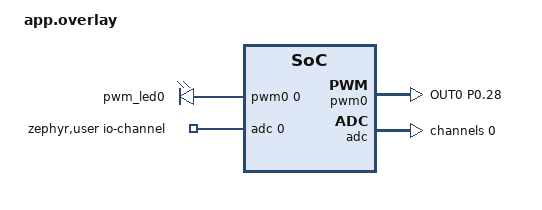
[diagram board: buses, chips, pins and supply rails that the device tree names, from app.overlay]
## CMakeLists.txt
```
cmake_minimum_required(VERSION 3.20.0)
find_package(Zephyr REQUIRED HINTS $ENV{ZEPHYR_BASE})

project(test_pwm_circuit)

target_sources(app PRIVATE src/main.c src/heater_PWM.c src/adc_temp.c src/control.c src/pid.c src/UI.c src/database.c src/display_uart.c src/filter.c)
```

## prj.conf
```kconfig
CONFIG_GPIO=y
CONFIG_PWM=y
CONFIG_LOG=y
CONFIG_PRINTK=n
CONFIG_ADC=y
CONFIG_CBPRINTF_FP_SUPPORT=y
```

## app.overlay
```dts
/ {
    aliases {
        heater = &pwm_led0;
    };

    pwmleds {
        compatible = "pwm-leds";
        pwm_led0: pwm_led_0 {
            /* Channel 0, 20ms period */
            pwms = <&pwm0 0 PWM_MSEC(20) PWM_POLARITY_NORMAL>;
        };
    };

    /* ADC User Shortcut */
    zephyr,user {
        io-channels = <&adc 0>;
    };
};

/* PWM Configuration */
&pwm0 {
    status = "okay";
    pinctrl-0 = <&pwm0_default>;
    pinctrl-1 = <&pwm0_sleep>;
    pinctrl-names = "default", "sleep";
};

&pinctrl {
    pwm0_default: pwm0_default {
        group1 {
            /* CRITICAL: Heater on Pin 28 */
            psels = <NRF_PSEL(PWM_OUT0, 0, 28)>;
        };
    };

    pwm0_sleep: pwm0_sleep {
        group1 {
            psels = <NRF_PSEL(PWM_OUT0, 0, 28)>;
            low-power-enable;
        };
    };
};

/* ADC Configuration */
&adc {
    status = "okay";
    #address-cells = <1>;
    #size-cells = <0>;

    channel@0 {
        reg = <0>;
        zephyr,gain = "ADC_GAIN_1_6";
        zephyr,reference = "ADC_REF_INTERNAL";
        zephyr,acquisition-time = <ADC_ACQ_TIME_DEFAULT>;
        zephyr,input-positive = <NRF_SAADC_AIN1>; 
        zephyr,resolution = <12>;
    };
};
```

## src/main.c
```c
#include <zephyr/kernel.h>
#include <zephyr/sys/printk.h>
#include "database.h"
#include "adc_temp.h"
#include "control.h"
#include "display_uart.h"
#include "UI.h"
#include "heater_PWM.h"
#include "filter.h"

#define DISPLAY_STACK 2048
#define STACK 1024

#define ADC_PRIORITY     1 
#define FILTER_PRIORITY  2 
#define CONTROL_PRIORITY 3 
#define PWM_PRIORITY     3 
#define LED_PRIORITY     5 
#define DISPLAY_PRIORITY 6

K_THREAD_DEFINE(adc_tid, STACK, adc_thread_entry, NULL, NULL, NULL, ADC_PRIORITY, 0, 0);
K_THREAD_DEFINE(filter_tid, STACK,  filter_thread_entry, NULL, NULL, NULL, FILTER_PRIORITY, 0, 0);
K_THREAD_DEFINE(control_tid, STACK,  control_thread, NULL, NULL, NULL, CONTROL_PRIORITY, 0, 0);
K_THREAD_DEFINE(pwm_tid, STACK,  pwm_thread_entry, NULL, NULL, NULL, PWM_PRIORITY, 0, 0);
K_THREAD_DEFINE(led_tid, STACK,  ui_led_thread_entry, NULL, NULL, NULL, LED_PRIORITY, 0, 0);
K_THREAD_DEFINE(disp_tid, DISPLAY_STACK, display_thread, NULL, NULL, NULL, DISPLAY_PRIORITY, 0, 0);

int main(void) 
{
    db_init();
    
    return 0;
}

/* RAM used: 2.66% (6976 B / 256 kB)

THREAD: ADC Acquisition
>> AVG TIME = 90 us
>> MAX TIME = 123 us

THREAD: Filter Logic
>> AVG TIME = 6 us
>> MAX TIME = 31 us

THREAD: Control Logic
>> AVG TIME = 12 us
>> MAX TIME = 31 us

THREAD: PWM Actuation
>> AVG TIME = 14 us
>> MAX TIME = 31 us

THREAD: LEDs
>> AVG TIME = 6 us
>> MAX TIME = 31 us

THREAD: Display
>> AVG TIME = 16 us
>> MAX TIME = 31 us

*/
```

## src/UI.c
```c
#include <zephyr/kernel.h>
#include <zephyr/drivers/gpio.h>
#include "database.h" 

// Hardware Aliases
#define SLEEP_TIME_MS 1000
#define DEBOUNCE_MS 200 // Average human Response Time

// Button Definition
#define BTN_ENABLE  DT_ALIAS(sw0)
#define BTN_INC     DT_ALIAS(sw1)
#define BTN_DEC     DT_ALIAS(sw3)

// LED Definition
#define LED_STATUS  DT_ALIAS(led0)
#define LED_NORM    DT_ALIAS(led1)
#define LED_LOW     DT_ALIAS(led2)
#define LED_HIGH    DT_ALIAS(led3)

static const struct gpio_dt_spec btn_enable = GPIO_DT_SPEC_GET(BTN_ENABLE, gpios);
static const struct gpio_dt_spec btn_inc    = GPIO_DT_SPEC_GET(BTN_INC, gpios);
static const struct gpio_dt_spec btn_dec    = GPIO_DT_SPEC_GET(BTN_DEC, gpios);

static const struct gpio_dt_spec led_status = GPIO_DT_SPEC_GET(LED_STATUS, gpios);
static const struct gpio_dt_spec led_norm   = GPIO_DT_SPEC_GET(LED_NORM, gpios);
static const struct gpio_dt_spec led_low    = GPIO_DT_SPEC_GET(LED_LOW, gpios);
static const struct gpio_dt_spec led_high   = GPIO_DT_SPEC_GET(LED_HIGH, gpios);

static struct gpio_callback data_enable, data_inc, data_dec;

// Debounce variables
// int64_t in all the debounce variables ensures continuous operation for millions of years
// A standard 32-bit int would overflow in approx. 24.8 days (2^31 ms)
static int64_t last_time_enable = 0;
static int64_t last_time_inc = 0;
static int64_t last_time_dec = 0;

void button_enable_handler() // Enable Button
{
    int64_t now = k_uptime_get();
    int64_t time_passed = now - last_time_enable;

    if (time_passed < DEBOUNCE_MS) {
        return; 
    } 
    else {
        last_time_enable = now;
    
        bool current_state = db_read_system_enable();
        db_write_system_enable(!current_state);
        gpio_pin_set_dt(&led_status, (int)(!current_state)); // led update
    }
}

void button_inc_handler()  // Target Increment Update
{ 
    int64_t now = k_uptime_get();
    int64_t time_passed = now - last_time_inc;

    if (time_passed < DEBOUNCE_MS) 
    {
        return;

    } else{
        last_time_inc = now;

        if (db_read_system_enable()) 
        {
        float val = db_read_target_temp();
        db_write_target_temp(val + 1.0f);
        }
    }
}

void button_dec_handler() // Target Decrement Update
{
    int64_t now = k_uptime_get();
    int64_t time_passed = now - last_time_dec;
    if (time_passed < DEBOUNCE_MS) 
    {
        return;

    } else{
        last_time_dec = now;

    if (db_read_system_enable())
    {
        float val = db_read_target_temp();
        db_write_target_temp(val - 1.0f);
    }
    }
}

int ui_init(void)   // UI Initialization
{
    
    if (!gpio_is_ready_dt(&btn_enable)) return -1;      

    gpio_pin_configure_dt(&btn_enable, GPIO_INPUT);
    gpio_pin_interrupt_configure_dt(&btn_enable, GPIO_INT_EDGE_TO_ACTIVE);     // On/Off Button Config
    gpio_pin_configure_dt(&btn_inc, GPIO_INPUT);
    gpio_pin_interrupt_configure_dt(&btn_inc, GPIO_INT_EDGE_TO_ACTIVE);        // Increment Button Config
    gpio_pin_configure_dt(&btn_dec, GPIO_INPUT);
    gpio_pin_interrupt_configure_dt(&btn_dec, GPIO_INT_EDGE_TO_ACTIVE);        // Decrement Button Config

    // LEDs Config
    gpio_pin_configure_dt(&led_status, GPIO_OUTPUT_INACTIVE);
    gpio_pin_configure_dt(&led_norm,   GPIO_OUTPUT_INACTIVE);
    gpio_pin_configure_dt(&led_low,    GPIO_OUTPUT_INACTIVE);
    gpio_pin_configure_dt(&led_high,   GPIO_OUTPUT_INACTIVE);                  

    // Associates a function whenever we click a Button
    gpio_init_callback(&data_enable, button_enable_handler, BIT(btn_enable.pin));
    gpio_add_callback(btn_enable.port, &data_enable);
    gpio_init_callback(&data_inc, button_inc_handler, BIT(btn_inc.pin)); 
    gpio_add_callback(btn_inc.port, &data_inc);
    gpio_init_callback(&data_dec, button_dec_handler, BIT(btn_dec.pin));
    gpio_add_callback(btn_dec.port, &data_dec);

    return 0;
}

void ui_led_thread_entry() 
{  
    if (ui_init() != 0)
    {
        printk("Error: UI Init Failed!\n");
    }  

    int64_t next_run_time = k_uptime_get();

    while (1)
    {
        next_run_time += 1000;

        if (!db_read_system_enable()) {
            gpio_pin_set_dt(&led_norm, 0);
            gpio_pin_set_dt(&led_low, 0);
            gpio_pin_set_dt(&led_high, 0);
        } else {
            float diff = db_read_target_temp() - db_read_current_temp();

            if (diff > 5) // Low Temperatures
            {       
                gpio_pin_set_dt(&led_low, 1);
                gpio_pin_set_dt(&led_norm, 0);
                gpio_pin_set_dt(&led_high, 0);
            } 
            else if (diff < -5) // High Temperatures
            { 
                gpio_pin_set_dt(&led_low, 0);
                gpio_pin_set_dt(&led_norm, 0);
                gpio_pin_set_dt(&led_high, 1);
            } 
            else 
            {                
                gpio_pin_set_dt(&led_low, 0);
                gpio_pin_set_dt(&led_norm, 1);
                gpio_pin_set_dt(&led_high, 0);
            }
        }
        int remaining = next_run_time - k_uptime_get();
        if (remaining > 0) k_msleep(remaining);    
    }
}

//K_THREAD_DEFINE(ui_led_tid, 1024, ui_led_thread_entry, NULL, NULL, NULL, 4, 0, 0);
```

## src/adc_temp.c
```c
#include <zephyr/kernel.h>
#include <zephyr/drivers/adc.h>
#include <zephyr/logging/log.h>
#include "adc_temp.h"
#include "database.h"

#define ADC_PERIOD_MS 1000

LOG_MODULE_REGISTER(ADC_Module, LOG_LEVEL_INF);

K_TIMER_DEFINE(adc_timer, NULL, NULL); // Drift-free, hardware-backed timing

static const struct adc_dt_spec adc_channel = ADC_DT_SPEC_GET_BY_IDX(DT_PATH(zephyr_user), 0);

static int16_t buf; 
static struct adc_sequence sequence = {
    .buffer = &buf,
    .buffer_size = sizeof(buf),

};

static float shared_raw_value = 0.0f; // Local variable to be filtered (no need to be stored in the DB)

// Local getter function
float adc_get_raw_internal(void) {
    return shared_raw_value;
}

void adc_temp_init(void) // ADC Initialization
{
    if (!adc_is_ready_dt(&adc_channel))
    {
        LOG_INF("ADC controller not ready");
    }

    int error = adc_channel_setup_dt(&adc_channel);
    if (error < 0)
    {
        LOG_INF("Could not setup channel (%d)", error);
    }

    error = adc_sequence_init_dt(&adc_channel, &sequence);
    if (error < 0) {
        LOG_INF("Error: Could not init sequence (%d)\n", error);
    }
}

void adc_thread_entry(void) {
    
    adc_temp_init();

    k_timer_start(&adc_timer, K_MSEC(ADC_PERIOD_MS), K_MSEC(ADC_PERIOD_MS));

    while (1) {
        k_timer_status_sync(&adc_timer);

        int err = adc_read(adc_channel.dev, &sequence);
        if (err == 0) {
            
            int32_t val_mv = buf; // 
            adc_raw_to_millivolts_dt(&adc_channel, &val_mv);
            float temp = (val_mv - 500) / 10.0f;

            shared_raw_value = temp;
            k_sem_give(&adc_data_sem); 
        } else {
            LOG_INF("ADC Read Error: %d\n", err);
        }
    }
}
```

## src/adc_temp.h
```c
#ifndef ADC_TEMP_H
#define ADC_TEMP_H

void adc_temp_init(void);

void adc_temp_read(void);

float adc_get_raw_internal(void);

void adc_thread_entry(void);

#endif
```

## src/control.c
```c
#include <zephyr/kernel.h>
#include <zephyr/logging/log.h>
#include "adc_temp.h"
#include "heater_PWM.h"
#include "pid.h"
#include "database.h"

LOG_MODULE_REGISTER(Control, LOG_LEVEL_INF);

// PID Parameters
#define KP  20.0f  
#define TI  130.0f 
#define TD  1.0f   

PID_Config my_pid;

K_TIMER_DEFINE(control_timer, NULL, NULL); // Drift-free, hardware-backed timing

void control_thread(void){
    
    pid_init(&my_pid, KP, TI, TD);

    k_timer_start(&control_timer, K_MSEC(1000), K_MSEC(1000));

    float dt = 1.0f; // period: 1000ms

    while (1)
    {
        k_timer_status_sync(&control_timer);
        
        // Local Reading Variables 
        float temp = db_read_current_temp();
        float target = db_read_target_temp();
        bool on = db_read_system_enable();

        int8_t power_command = 0;
        
        if (!on) {
            power_command = 0;
            pid_init(&my_pid, KP, TI, TD); 
        } else {
            power_command = (int8_t)pid_compute(&my_pid, target, temp, dt); // PID math doing its job
        }

        db_write_current_power(power_command); // current state goes straight to the database

        k_sem_give(&pwm_data_sem);
    }
    }
  
```

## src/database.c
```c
#include "database.h"

// 1. PRIVATE DATA
static volatile float  target_temp = 19.0f;
static float  current_temp = 0.0f;
//static float  raw_temp = 0.0f;  // former test
static int8_t    current_power = 0;
static volatile bool   system_enable = false;

// Semaphore Definition (they start locked)
K_SEM_DEFINE(adc_data_sem, 0, 1); 
K_SEM_DEFINE(pwm_data_sem, 0, 1);

K_MUTEX_DEFINE(db_mutex);

void db_init(void) {
    // Mutex auto-initialization
}

// ACCESS FUNCTIONS (no mutex needed in volatile variables)

/* Mutex Removed for ISR Safety
target_temp is written by an Interrupt Service Routine (ISR) via buttons.
ISRs cannot wait for mutexes. Therefore, the variable is declared 'volatile'
to prevent compiler caching which avoids race conditions without locking.
 */

void db_write_target_temp(float new_target) {
    //k_mutex_lock(&db_mutex, K_FOREVER);

    // Safety Limits
    if (new_target > 60.0f) new_target = 60.0f; 
    if (new_target < 20.0f) new_target = 20.0f;

    target_temp = new_target;
    //k_mutex_unlock(&db_mutex);
}

float db_read_target_temp(void) {
    k_mutex_lock(&db_mutex, K_FOREVER);
    float val = target_temp;
    k_mutex_unlock(&db_mutex);
    return val;
}

void db_write_current_temp(float new_temp) {
    k_mutex_lock(&db_mutex, K_FOREVER);
    current_temp = new_temp;
    k_mutex_unlock(&db_mutex);
}

float db_read_current_temp(void) {
    k_mutex_lock(&db_mutex, K_FOREVER);
    float val = current_temp;
    k_mutex_unlock(&db_mutex);
    return val;
}

void db_write_current_power(int8_t new_power) {
    k_mutex_lock(&db_mutex, K_FOREVER);
    current_power = new_power;
    k_mutex_unlock(&db_mutex);
}

int8_t db_read_current_power(void) {
    k_mutex_lock(&db_mutex, K_FOREVER);
    int8_t val = current_power;
    k_mutex_unlock(&db_mutex);
    return val;
}

void db_write_system_enable(bool enable) {
    //k_mutex_lock(&db_mutex, K_FOREVER);
    system_enable = enable;
    //k_mutex_unlock(&db_mutex);
}

bool db_read_system_enable(void) {
    k_mutex_lock(&db_mutex, K_FOREVER);
    bool val = system_enable;
    k_mutex_unlock(&db_mutex);
    return val;
}

/*  no longer used (previous test )

void db_write_raw_temp(float val) {
    k_mutex_lock(&db_mutex, K_FOREVER);
    raw_temp = val;
    k_mutex_unlock(&db_mutex);
}

float db_read_raw_temp(void) {
    k_mutex_lock(&db_mutex, K_FOREVER);
    float val = raw_temp;
    k_mutex_unlock(&db_mutex);
    return val;
}
*/
```

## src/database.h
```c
#ifndef DATABASE_H
#define DATABASE_H

#include <zephyr/kernel.h>

extern struct k_sem adc_data_sem;
extern struct k_sem pwm_data_sem;

void db_init(void); // Initialize the database (mutex)

// WRITERS
void db_write_target_temp(float new_target);
void db_write_current_temp(float new_temp);
void db_write_current_power(int8_t new_power);
void db_write_system_enable(bool enable);

// READERS
float db_read_target_temp(void);
float db_read_current_temp(void);
int8_t   db_read_current_power(void);
bool  db_read_system_enable(void);

//void db_write_raw_temp(float val);
//float db_read_raw_temp(void);

#endif
```

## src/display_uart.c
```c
#include <zephyr/kernel.h>
#include <zephyr/logging/log.h>
#include "database.h"

LOG_MODULE_REGISTER(Display, LOG_LEVEL_INF); // Module Registration

K_TIMER_DEFINE(display_timer, NULL, NULL); // Drift-free, hardware-backed timing

void display_thread(void) {

    LOG_INF("THERMOSTAT STARTING");
    LOG_INF("System Ready. Press Button 1 to Start.");

    k_timer_start(&display_timer, K_MSEC(1000), K_MSEC(1000));

    // Local Printing Variables
    bool on;
    float target;
    float current;
    int8_t power;

    while (1) {
        k_timer_status_sync(&display_timer);

        // Reading Process
        on = db_read_system_enable();
        target = db_read_target_temp();
        current = db_read_current_temp();
        power = db_read_current_power();

        if (!on) {
            LOG_INF("System: [OFF] (Standby)");
        } 
        else {
            const char *status_msg;
            float diff = target - current;

            if (diff > 5.0f)       status_msg = "[HEATING]";
            else if (diff < -5.0f) status_msg = "[COOLING]";
            else                   status_msg = "[STABLE]";

            LOG_INF("System: [ON] | TGT: %.1f C | CUR: %.1f C | PWR: %d%% | %s", 
                   (double)target, (double)current, power, status_msg); // full dashboard line
        }
}
}
```

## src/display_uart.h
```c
#ifndef DISPLAY_UART_H
#define DISPLAY_UART_H

void display_thread(void);

#endif
```

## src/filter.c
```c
#include <zephyr/kernel.h>
#include "filter.h"
#include "adc_temp.h"
#include "database.h"

void filter_thread_entry(void) {
    
    static float prev_temp = 0.0f;
    static bool first_run = true;

    while (1) {
/* SYNCHRONIZATION:
 * This thread is Event-Driven. It consumes 0% CPU while waiting.
 * It is effectively "clocked" by the ADC thread via semaphore.
 * ADC finishes -> Signals Semaphore -> Filter Wakes Up immediately.
 * This guarantees minimal latency between data acquisition and filtering.
 */
        // WAIT for the ADC to signal (Blocking!)
        k_sem_take(&adc_data_sem, K_FOREVER); // This thread sleeps here until ADC calls k_sem_give.

        float raw = adc_get_raw_internal(); // get raw data directly from ADC module

        float filtered;
        if (first_run) {
            filtered = raw;
            prev_temp = raw;
            first_run = false;
        } else {
            filtered = (raw + prev_temp) / 2.0f; // Moving Average
            prev_temp = raw;
        }

        db_write_current_temp(filtered); // PUBLISH to Database
    }
}
```

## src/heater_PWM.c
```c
#include <zephyr/kernel.h>
#include <zephyr/drivers/pwm.h>
#include <zephyr/logging/log.h>
#include "heater_PWM.h"
#include "database.h"

LOG_MODULE_REGISTER(Heater_Module, LOG_LEVEL_INF);

static const struct pwm_dt_spec heater_dev = PWM_DT_SPEC_GET(DT_ALIAS(heater));

static void set_pwm(uint8_t intensity) {  
  
    if (intensity > 100) intensity = 100;
    uint32_t pulse_ns = (intensity * heater_dev.period) / 100;
    int err = pwm_set_pulse_dt(&heater_dev, pulse_ns);
    if (err) {
        printk("PWM set failed: %d", err);
    }
}

void heater_init(void) // Heater Initialization
{
    if (!pwm_is_ready_dt(&heater_dev)) {
        printk("Error: PWM device %s is not ready", heater_dev.dev->name);
        return;
    }

    set_pwm(0);
    printk("Heater Initialized (PWM)\n");
}

void pwm_thread_entry(void) {
    
    heater_init();
    set_pwm(0);

    while(1) {
        k_sem_take(&pwm_data_sem, K_FOREVER);

        int8_t power = db_read_current_power();
        set_pwm(power);
    }
}
```

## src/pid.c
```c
#include <zephyr/kernel.h>
#include "pid.h"

void pid_init(PID_Config *pid, float Kp, float Ti, float Td) // PID Initialization
{
    pid->Kp = Kp;
    pid->Ti = Ti;
    pid->Td = Td;
    
    pid->integral = 0.0f;
    pid->prev_error = 0.0f;
    
    // Output Limits (0% to 100% Power)
    pid->out_min = 0.0f;
    pid->out_max = 100.0f;
}

int pid_compute(PID_Config *pid, float setpoint, float current_val, float dt) {
    float error = setpoint - current_val;

    float P = pid->Kp * error; // Proportional Component

    pid->integral += error * dt; 
    float I = (pid->Kp / pid->Ti) * pid->integral; // Integrative Component

    float derivative = (error - pid->prev_error) / dt;
    float D = (pid->Kp * pid->Td) * derivative; // Derivative Component

    float output = P + I + D; // Total
    
    if (output > pid->out_max) {
        output = pid->out_max;
        if (error > 0) {
            pid->integral -= error * dt; 
        }
    } else if (output < pid->out_min) {
        output = pid->out_min;
        if (error < 0) {
            pid->integral -= error * dt;
        }
    }

    pid->prev_error = error; // Keep state

    return (int)output;
}
```
